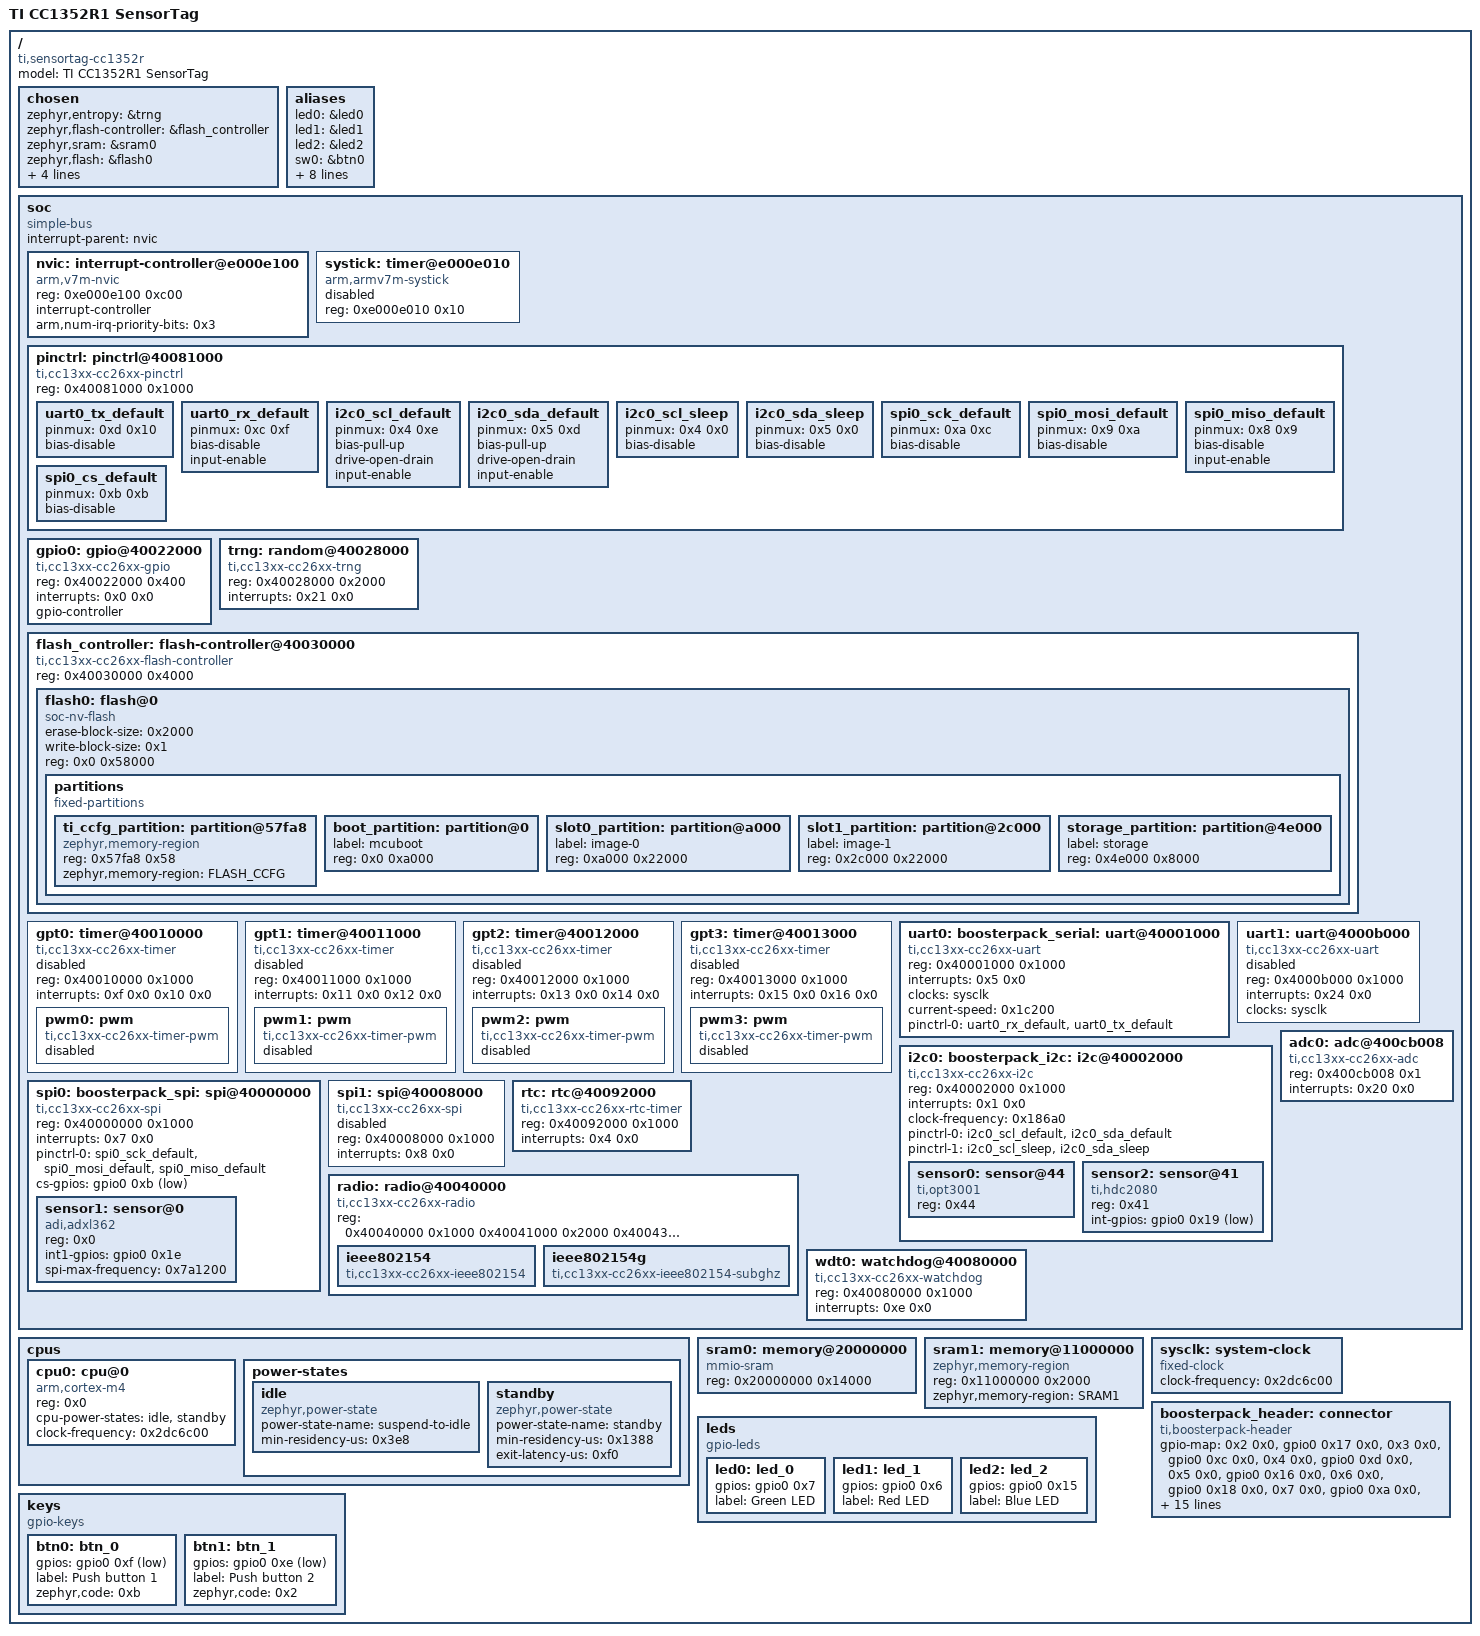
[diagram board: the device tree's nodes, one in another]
/dts-v1/;

/* node '/' defined in zephyr/dts/common/skeleton.dtsi:9 */
/ {
	#address-cells = < 0x1 >;            /* in zephyr/dts/common/skeleton.dtsi:10 */
	#size-cells = < 0x1 >;               /* in zephyr/dts/common/skeleton.dtsi:11 */
	model = "TI CC1352R1 SensorTag";     /* in zephyr/boards/ti/cc1352r_sensortag/cc1352r_sensortag.dts:18 */
	compatible = "ti,sensortag-cc1352r"; /* in zephyr/boards/ti/cc1352r_sensortag/cc1352r_sensortag.dts:19 */

	/* node '/chosen' defined in zephyr/dts/common/skeleton.dtsi:13 */
	chosen {
		zephyr,entropy = &trng;                      /* in zephyr/dts/arm/ti/cc13xx_cc26xx.dtsi:15 */
		zephyr,flash-controller = &flash_controller; /* in zephyr/dts/arm/ti/cc13xx_cc26xx.dtsi:16 */
		zephyr,sram = &sram0;                        /* in zephyr/boards/ti/cc1352r_sensortag/cc1352r_sensortag.dts:37 */
		zephyr,flash = &flash0;                      /* in zephyr/boards/ti/cc1352r_sensortag/cc1352r_sensortag.dts:38 */
		zephyr,console = &uart0;                     /* in zephyr/boards/ti/cc1352r_sensortag/cc1352r_sensortag.dts:39 */
		zephyr,shell-uart = &uart0;                  /* in zephyr/boards/ti/cc1352r_sensortag/cc1352r_sensortag.dts:40 */
		zephyr,ieee802154 = &ieee802154;             /* in zephyr/boards/ti/cc1352r_sensortag/cc1352r_sensortag.dts:41 */
		zephyr,code-partition = &slot0_partition;    /* in zephyr/boards/ti/cc1352r_sensortag/cc1352r_sensortag.dts:42 */
	};

	/* node '/aliases' defined in zephyr/dts/common/skeleton.dtsi:15 */
	aliases {
		led0 = &led0;            /* in zephyr/boards/ti/cc1352r_sensortag/cc1352r_sensortag.dts:22 */
		led1 = &led1;            /* in zephyr/boards/ti/cc1352r_sensortag/cc1352r_sensortag.dts:23 */
		led2 = &led2;            /* in zephyr/boards/ti/cc1352r_sensortag/cc1352r_sensortag.dts:24 */
		sw0 = &btn0;             /* in zephyr/boards/ti/cc1352r_sensortag/cc1352r_sensortag.dts:25 */
		sw1 = &btn1;             /* in zephyr/boards/ti/cc1352r_sensortag/cc1352r_sensortag.dts:26 */
		sensor0 = &sensor0;      /* in zephyr/boards/ti/cc1352r_sensortag/cc1352r_sensortag.dts:27 */
		sensor1 = &sensor1;      /* in zephyr/boards/ti/cc1352r_sensortag/cc1352r_sensortag.dts:28 */
		sensor2 = &sensor2;      /* in zephyr/boards/ti/cc1352r_sensortag/cc1352r_sensortag.dts:29 */
		accel0 = &sensor1;       /* in zephyr/boards/ti/cc1352r_sensortag/cc1352r_sensortag.dts:30 */
		watchdog0 = &wdt0;       /* in zephyr/boards/ti/cc1352r_sensortag/cc1352r_sensortag.dts:31 */
		mcuboot-led0 = &led1;    /* in zephyr/boards/ti/cc1352r_sensortag/cc1352r_sensortag.dts:32 */
		mcuboot-button0 = &btn1; /* in zephyr/boards/ti/cc1352r_sensortag/cc1352r_sensortag.dts:33 */
	};

	/* node '/soc' defined in zephyr/dts/arm/armv7-m.dtsi:6 */
	soc {
		#address-cells = < 0x1 >;     /* in zephyr/dts/arm/armv7-m.dtsi:7 */
		#size-cells = < 0x1 >;        /* in zephyr/dts/arm/armv7-m.dtsi:8 */
		compatible = "simple-bus";    /* in zephyr/dts/arm/armv7-m.dtsi:9 */
		interrupt-parent = < &nvic >; /* in zephyr/dts/arm/armv7-m.dtsi:10 */
		ranges;                       /* in zephyr/dts/arm/armv7-m.dtsi:11 */

		/* node '/soc/interrupt-controller@e000e100' defined in zephyr/dts/arm/armv7-m.dtsi:13 */
		nvic: interrupt-controller@e000e100 {
			#address-cells = < 0x1 >;            /* in zephyr/dts/arm/armv7-m.dtsi:14 */
			compatible = "arm,v7m-nvic";         /* in zephyr/dts/arm/armv7-m.dtsi:15 */
			reg = < 0xe000e100 0xc00 >;          /* in zephyr/dts/arm/armv7-m.dtsi:16 */
			interrupt-controller;                /* in zephyr/dts/arm/armv7-m.dtsi:17 */
			#interrupt-cells = < 0x2 >;          /* in zephyr/dts/arm/armv7-m.dtsi:18 */
			arm,num-irq-priority-bits = < 0x3 >; /* in zephyr/dts/arm/ti/cc13xx_cc26xx.dtsi:246 */
			phandle = < 0x1 >;                   /* in zephyr/dts/arm/armv7-m.dtsi:10 */
		};

		/* node '/soc/timer@e000e010' defined in zephyr/dts/arm/armv7-m.dtsi:21 */
		systick: timer@e000e010 {
			compatible = "arm,armv7m-systick"; /* in zephyr/dts/arm/armv7-m.dtsi:22 */
			reg = < 0xe000e010 0x10 >;         /* in zephyr/dts/arm/armv7-m.dtsi:23 */
			status = "disabled";               /* in zephyr/dts/arm/ti/cc13xx_cc26xx.dtsi:250 */
		};

		/* node '/soc/pinctrl@40081000' defined in zephyr/dts/arm/ti/cc13xx_cc26xx.dtsi:64 */
		pinctrl: pinctrl@40081000 {
			compatible = "ti,cc13xx-cc26xx-pinctrl"; /* in zephyr/dts/arm/ti/cc13xx_cc26xx.dtsi:65 */
			reg = < 0x40081000 0x1000 >;             /* in zephyr/dts/arm/ti/cc13xx_cc26xx.dtsi:66 */

			/* node '/soc/pinctrl@40081000/uart0_tx_default' defined in zephyr/boards/ti/cc1352r_sensortag/cc1352r_sensortag-pinctrl.dtsi:11 */
			uart0_tx_default: uart0_tx_default {
				pinmux = < 0xd 0x10 >; /* in zephyr/boards/ti/cc1352r_sensortag/cc1352r_sensortag-pinctrl.dtsi:12 */
				bias-disable;          /* in zephyr/boards/ti/cc1352r_sensortag/cc1352r_sensortag-pinctrl.dtsi:13 */
				phandle = < 0x4 >;     /* in zephyr/boards/ti/cc1352r_sensortag/cc1352r_sensortag.dts:131 */
			};

			/* node '/soc/pinctrl@40081000/uart0_rx_default' defined in zephyr/boards/ti/cc1352r_sensortag/cc1352r_sensortag-pinctrl.dtsi:16 */
			uart0_rx_default: uart0_rx_default {
				pinmux = < 0xc 0xf >; /* in zephyr/boards/ti/cc1352r_sensortag/cc1352r_sensortag-pinctrl.dtsi:17 */
				bias-disable;         /* in zephyr/boards/ti/cc1352r_sensortag/cc1352r_sensortag-pinctrl.dtsi:18 */
				input-enable;         /* in zephyr/boards/ti/cc1352r_sensortag/cc1352r_sensortag-pinctrl.dtsi:19 */
				phandle = < 0x3 >;    /* in zephyr/boards/ti/cc1352r_sensortag/cc1352r_sensortag.dts:131 */
			};

			/* node '/soc/pinctrl@40081000/i2c0_scl_default' defined in zephyr/boards/ti/cc1352r_sensortag/cc1352r_sensortag-pinctrl.dtsi:23 */
			i2c0_scl_default: i2c0_scl_default {
				pinmux = < 0x4 0xe >; /* in zephyr/boards/ti/cc1352r_sensortag/cc1352r_sensortag-pinctrl.dtsi:24 */
				bias-pull-up;         /* in zephyr/boards/ti/cc1352r_sensortag/cc1352r_sensortag-pinctrl.dtsi:25 */
				drive-open-drain;     /* in zephyr/boards/ti/cc1352r_sensortag/cc1352r_sensortag-pinctrl.dtsi:26 */
				input-enable;         /* in zephyr/boards/ti/cc1352r_sensortag/cc1352r_sensortag-pinctrl.dtsi:27 */
				phandle = < 0x5 >;    /* in zephyr/boards/ti/cc1352r_sensortag/cc1352r_sensortag.dts:137 */
			};

			/* node '/soc/pinctrl@40081000/i2c0_sda_default' defined in zephyr/boards/ti/cc1352r_sensortag/cc1352r_sensortag-pinctrl.dtsi:30 */
			i2c0_sda_default: i2c0_sda_default {
				pinmux = < 0x5 0xd >; /* in zephyr/boards/ti/cc1352r_sensortag/cc1352r_sensortag-pinctrl.dtsi:31 */
				bias-pull-up;         /* in zephyr/boards/ti/cc1352r_sensortag/cc1352r_sensortag-pinctrl.dtsi:32 */
				drive-open-drain;     /* in zephyr/boards/ti/cc1352r_sensortag/cc1352r_sensortag-pinctrl.dtsi:33 */
				input-enable;         /* in zephyr/boards/ti/cc1352r_sensortag/cc1352r_sensortag-pinctrl.dtsi:34 */
				phandle = < 0x6 >;    /* in zephyr/boards/ti/cc1352r_sensortag/cc1352r_sensortag.dts:137 */
			};

			/* node '/soc/pinctrl@40081000/i2c0_scl_sleep' defined in zephyr/boards/ti/cc1352r_sensortag/cc1352r_sensortag-pinctrl.dtsi:37 */
			i2c0_scl_sleep: i2c0_scl_sleep {
				pinmux = < 0x4 0x0 >; /* in zephyr/boards/ti/cc1352r_sensortag/cc1352r_sensortag-pinctrl.dtsi:38 */
				bias-disable;         /* in zephyr/boards/ti/cc1352r_sensortag/cc1352r_sensortag-pinctrl.dtsi:39 */
				phandle = < 0x7 >;    /* in zephyr/boards/ti/cc1352r_sensortag/cc1352r_sensortag.dts:138 */
			};

			/* node '/soc/pinctrl@40081000/i2c0_sda_sleep' defined in zephyr/boards/ti/cc1352r_sensortag/cc1352r_sensortag-pinctrl.dtsi:42 */
			i2c0_sda_sleep: i2c0_sda_sleep {
				pinmux = < 0x5 0x0 >; /* in zephyr/boards/ti/cc1352r_sensortag/cc1352r_sensortag-pinctrl.dtsi:43 */
				bias-disable;         /* in zephyr/boards/ti/cc1352r_sensortag/cc1352r_sensortag-pinctrl.dtsi:44 */
				phandle = < 0x8 >;    /* in zephyr/boards/ti/cc1352r_sensortag/cc1352r_sensortag.dts:138 */
			};

			/* node '/soc/pinctrl@40081000/spi0_sck_default' defined in zephyr/boards/ti/cc1352r_sensortag/cc1352r_sensortag-pinctrl.dtsi:48 */
			spi0_sck_default: spi0_sck_default {
				pinmux = < 0xa 0xc >; /* in zephyr/boards/ti/cc1352r_sensortag/cc1352r_sensortag-pinctrl.dtsi:49 */
				bias-disable;         /* in zephyr/boards/ti/cc1352r_sensortag/cc1352r_sensortag-pinctrl.dtsi:50 */
				phandle = < 0xa >;    /* in zephyr/boards/ti/cc1352r_sensortag/cc1352r_sensortag.dts:155 */
			};

			/* node '/soc/pinctrl@40081000/spi0_mosi_default' defined in zephyr/boards/ti/cc1352r_sensortag/cc1352r_sensortag-pinctrl.dtsi:53 */
			spi0_mosi_default: spi0_mosi_default {
				pinmux = < 0x9 0xa >; /* in zephyr/boards/ti/cc1352r_sensortag/cc1352r_sensortag-pinctrl.dtsi:54 */
				bias-disable;         /* in zephyr/boards/ti/cc1352r_sensortag/cc1352r_sensortag-pinctrl.dtsi:55 */
				phandle = < 0xb >;    /* in zephyr/boards/ti/cc1352r_sensortag/cc1352r_sensortag.dts:155 */
			};

			/* node '/soc/pinctrl@40081000/spi0_miso_default' defined in zephyr/boards/ti/cc1352r_sensortag/cc1352r_sensortag-pinctrl.dtsi:58 */
			spi0_miso_default: spi0_miso_default {
				pinmux = < 0x8 0x9 >; /* in zephyr/boards/ti/cc1352r_sensortag/cc1352r_sensortag-pinctrl.dtsi:59 */
				bias-disable;         /* in zephyr/boards/ti/cc1352r_sensortag/cc1352r_sensortag-pinctrl.dtsi:60 */
				input-enable;         /* in zephyr/boards/ti/cc1352r_sensortag/cc1352r_sensortag-pinctrl.dtsi:61 */
				phandle = < 0xc >;    /* in zephyr/boards/ti/cc1352r_sensortag/cc1352r_sensortag.dts:155 */
			};

			/* node '/soc/pinctrl@40081000/spi0_cs_default' defined in zephyr/boards/ti/cc1352r_sensortag/cc1352r_sensortag-pinctrl.dtsi:64 */
			spi0_cs_default: spi0_cs_default {
				pinmux = < 0xb 0xb >; /* in zephyr/boards/ti/cc1352r_sensortag/cc1352r_sensortag-pinctrl.dtsi:65 */
				bias-disable;         /* in zephyr/boards/ti/cc1352r_sensortag/cc1352r_sensortag-pinctrl.dtsi:66 */
			};
		};

		/* node '/soc/gpio@40022000' defined in zephyr/dts/arm/ti/cc13xx_cc26xx.dtsi:69 */
		gpio0: gpio@40022000 {
			compatible = "ti,cc13xx-cc26xx-gpio"; /* in zephyr/dts/arm/ti/cc13xx_cc26xx.dtsi:70 */
			reg = < 0x40022000 0x400 >;           /* in zephyr/dts/arm/ti/cc13xx_cc26xx.dtsi:71 */
			interrupts = < 0x0 0x0 >;             /* in zephyr/dts/arm/ti/cc13xx_cc26xx.dtsi:72 */
			gpio-controller;                      /* in zephyr/dts/arm/ti/cc13xx_cc26xx.dtsi:74 */
			#gpio-cells = < 0x2 >;                /* in zephyr/dts/arm/ti/cc13xx_cc26xx.dtsi:75 */
			status = "okay";                      /* in zephyr/boards/ti/cc1352r_sensortag/cc1352r_sensortag.dts:121 */
			phandle = < 0x9 >;                    /* in zephyr/boards/ti/cc1352r_sensortag/cc1352r_sensortag.dts:149 */
		};

		/* node '/soc/random@40028000' defined in zephyr/dts/arm/ti/cc13xx_cc26xx.dtsi:78 */
		trng: random@40028000 {
			compatible = "ti,cc13xx-cc26xx-trng"; /* in zephyr/dts/arm/ti/cc13xx_cc26xx.dtsi:79 */
			reg = < 0x40028000 0x2000 >;          /* in zephyr/dts/arm/ti/cc13xx_cc26xx.dtsi:80 */
			interrupts = < 0x21 0x0 >;            /* in zephyr/dts/arm/ti/cc13xx_cc26xx.dtsi:81 */
			status = "okay";                      /* in zephyr/boards/ti/cc1352r_sensortag/cc1352r_sensortag.dts:117 */
		};

		/* node '/soc/flash-controller@40030000' defined in zephyr/dts/arm/ti/cc13xx_cc26xx.dtsi:85 */
		flash_controller: flash-controller@40030000 {
			compatible = "ti,cc13xx-cc26xx-flash-controller"; /* in zephyr/dts/arm/ti/cc13xx_cc26xx.dtsi:86 */
			reg = < 0x40030000 0x4000 >;                      /* in zephyr/dts/arm/ti/cc13xx_cc26xx.dtsi:87 */
			#address-cells = < 0x1 >;                         /* in zephyr/dts/arm/ti/cc13xx_cc26xx.dtsi:89 */
			#size-cells = < 0x1 >;                            /* in zephyr/dts/arm/ti/cc13xx_cc26xx.dtsi:90 */

			/* node '/soc/flash-controller@40030000/flash@0' defined in zephyr/dts/arm/ti/cc13xx_cc26xx.dtsi:92 */
			flash0: flash@0 {
				compatible = "soc-nv-flash";   /* in zephyr/dts/arm/ti/cc13xx_cc26xx.dtsi:93 */
				erase-block-size = < 0x2000 >; /* in zephyr/dts/arm/ti/cc13xx_cc26xx.dtsi:94 */
				write-block-size = < 0x1 >;    /* in zephyr/dts/arm/ti/cc13xx_cc26xx.dtsi:95 */
				reg = < 0x0 0x58000 >;         /* in zephyr/dts/arm/ti/cc1352r.dtsi:17 */

				/* node '/soc/flash-controller@40030000/flash@0/partitions' defined in zephyr/dts/arm/ti/cc1352r.dtsi:19 */
				partitions {
					compatible = "fixed-partitions"; /* in zephyr/dts/arm/ti/cc1352r.dtsi:20 */
					#address-cells = < 0x1 >;        /* in zephyr/dts/arm/ti/cc1352r.dtsi:21 */
					#size-cells = < 0x1 >;           /* in zephyr/dts/arm/ti/cc1352r.dtsi:22 */

					/* node '/soc/flash-controller@40030000/flash@0/partitions/partition@57fa8' defined in zephyr/dts/arm/ti/cc1352r.dtsi:25 */
					ti_ccfg_partition: partition@57fa8 {
						compatible = "zephyr,memory-region"; /* in zephyr/dts/arm/ti/cc1352r.dtsi:26 */
						reg = < 0x57fa8 0x58 >;              /* in zephyr/dts/arm/ti/cc1352r.dtsi:27 */
						zephyr,memory-region = "FLASH_CCFG"; /* in zephyr/dts/arm/ti/cc1352r.dtsi:28 */
					};

					/* node '/soc/flash-controller@40030000/flash@0/partitions/partition@0' defined in zephyr/boards/ti/cc1352r_sensortag/cc1352r_sensortag.dts:84 */
					boot_partition: partition@0 {
						label = "mcuboot";    /* in zephyr/boards/ti/cc1352r_sensortag/cc1352r_sensortag.dts:85 */
						reg = < 0x0 0xa000 >; /* in zephyr/boards/ti/cc1352r_sensortag/cc1352r_sensortag.dts:86 */
					};

					/* node '/soc/flash-controller@40030000/flash@0/partitions/partition@a000' defined in zephyr/boards/ti/cc1352r_sensortag/cc1352r_sensortag.dts:90 */
					slot0_partition: partition@a000 {
						label = "image-0";        /* in zephyr/boards/ti/cc1352r_sensortag/cc1352r_sensortag.dts:91 */
						reg = < 0xa000 0x22000 >; /* in zephyr/boards/ti/cc1352r_sensortag/cc1352r_sensortag.dts:92 */
					};

					/* node '/soc/flash-controller@40030000/flash@0/partitions/partition@2c000' defined in zephyr/boards/ti/cc1352r_sensortag/cc1352r_sensortag.dts:95 */
					slot1_partition: partition@2c000 {
						label = "image-1";         /* in zephyr/boards/ti/cc1352r_sensortag/cc1352r_sensortag.dts:96 */
						reg = < 0x2c000 0x22000 >; /* in zephyr/boards/ti/cc1352r_sensortag/cc1352r_sensortag.dts:97 */
					};

					/* node '/soc/flash-controller@40030000/flash@0/partitions/partition@4e000' defined in zephyr/boards/ti/cc1352r_sensortag/cc1352r_sensortag.dts:101 */
					storage_partition: partition@4e000 {
						label = "storage";        /* in zephyr/boards/ti/cc1352r_sensortag/cc1352r_sensortag.dts:102 */
						reg = < 0x4e000 0x8000 >; /* in zephyr/boards/ti/cc1352r_sensortag/cc1352r_sensortag.dts:103 */
					};
				};
			};
		};

		/* node '/soc/timer@40010000' defined in zephyr/dts/arm/ti/cc13xx_cc26xx.dtsi:99 */
		gpt0: timer@40010000 {
			compatible = "ti,cc13xx-cc26xx-timer"; /* in zephyr/dts/arm/ti/cc13xx_cc26xx.dtsi:100 */
			reg = < 0x40010000 0x1000 >;           /* in zephyr/dts/arm/ti/cc13xx_cc26xx.dtsi:101 */
			interrupts = < 0xf 0x0 0x10 0x0 >;     /* in zephyr/dts/arm/ti/cc13xx_cc26xx.dtsi:102 */
			interrupt-names = "gpt0a",
			                  "gpt0b";             /* in zephyr/dts/arm/ti/cc13xx_cc26xx.dtsi:103 */
			status = "disabled";                   /* in zephyr/dts/arm/ti/cc13xx_cc26xx.dtsi:104 */

			/* node '/soc/timer@40010000/pwm' defined in zephyr/dts/arm/ti/cc13xx_cc26xx.dtsi:106 */
			pwm0: pwm {
				compatible = "ti,cc13xx-cc26xx-timer-pwm"; /* in zephyr/dts/arm/ti/cc13xx_cc26xx.dtsi:107 */
				#pwm-cells = < 0x3 >;                      /* in zephyr/dts/arm/ti/cc13xx_cc26xx.dtsi:108 */
				status = "disabled";                       /* in zephyr/dts/arm/ti/cc13xx_cc26xx.dtsi:109 */
			};
		};

		/* node '/soc/timer@40011000' defined in zephyr/dts/arm/ti/cc13xx_cc26xx.dtsi:113 */
		gpt1: timer@40011000 {
			compatible = "ti,cc13xx-cc26xx-timer"; /* in zephyr/dts/arm/ti/cc13xx_cc26xx.dtsi:114 */
			reg = < 0x40011000 0x1000 >;           /* in zephyr/dts/arm/ti/cc13xx_cc26xx.dtsi:115 */
			interrupts = < 0x11 0x0 0x12 0x0 >;    /* in zephyr/dts/arm/ti/cc13xx_cc26xx.dtsi:116 */
			interrupt-names = "gpt1a",
			                  "gpt1b";             /* in zephyr/dts/arm/ti/cc13xx_cc26xx.dtsi:117 */
			status = "disabled";                   /* in zephyr/dts/arm/ti/cc13xx_cc26xx.dtsi:118 */

			/* node '/soc/timer@40011000/pwm' defined in zephyr/dts/arm/ti/cc13xx_cc26xx.dtsi:120 */
			pwm1: pwm {
				compatible = "ti,cc13xx-cc26xx-timer-pwm"; /* in zephyr/dts/arm/ti/cc13xx_cc26xx.dtsi:121 */
				#pwm-cells = < 0x3 >;                      /* in zephyr/dts/arm/ti/cc13xx_cc26xx.dtsi:122 */
				status = "disabled";                       /* in zephyr/dts/arm/ti/cc13xx_cc26xx.dtsi:123 */
			};
		};

		/* node '/soc/timer@40012000' defined in zephyr/dts/arm/ti/cc13xx_cc26xx.dtsi:127 */
		gpt2: timer@40012000 {
			compatible = "ti,cc13xx-cc26xx-timer"; /* in zephyr/dts/arm/ti/cc13xx_cc26xx.dtsi:128 */
			reg = < 0x40012000 0x1000 >;           /* in zephyr/dts/arm/ti/cc13xx_cc26xx.dtsi:129 */
			interrupts = < 0x13 0x0 0x14 0x0 >;    /* in zephyr/dts/arm/ti/cc13xx_cc26xx.dtsi:130 */
			interrupt-names = "gpt2a",
			                  "gpt2b";             /* in zephyr/dts/arm/ti/cc13xx_cc26xx.dtsi:131 */
			status = "disabled";                   /* in zephyr/dts/arm/ti/cc13xx_cc26xx.dtsi:132 */

			/* node '/soc/timer@40012000/pwm' defined in zephyr/dts/arm/ti/cc13xx_cc26xx.dtsi:134 */
			pwm2: pwm {
				compatible = "ti,cc13xx-cc26xx-timer-pwm"; /* in zephyr/dts/arm/ti/cc13xx_cc26xx.dtsi:135 */
				#pwm-cells = < 0x3 >;                      /* in zephyr/dts/arm/ti/cc13xx_cc26xx.dtsi:136 */
				status = "disabled";                       /* in zephyr/dts/arm/ti/cc13xx_cc26xx.dtsi:137 */
			};
		};

		/* node '/soc/timer@40013000' defined in zephyr/dts/arm/ti/cc13xx_cc26xx.dtsi:141 */
		gpt3: timer@40013000 {
			compatible = "ti,cc13xx-cc26xx-timer"; /* in zephyr/dts/arm/ti/cc13xx_cc26xx.dtsi:142 */
			reg = < 0x40013000 0x1000 >;           /* in zephyr/dts/arm/ti/cc13xx_cc26xx.dtsi:143 */
			interrupts = < 0x15 0x0 0x16 0x0 >;    /* in zephyr/dts/arm/ti/cc13xx_cc26xx.dtsi:144 */
			interrupt-names = "gpt3a",
			                  "gpt3b";             /* in zephyr/dts/arm/ti/cc13xx_cc26xx.dtsi:145 */
			status = "disabled";                   /* in zephyr/dts/arm/ti/cc13xx_cc26xx.dtsi:146 */

			/* node '/soc/timer@40013000/pwm' defined in zephyr/dts/arm/ti/cc13xx_cc26xx.dtsi:148 */
			pwm3: pwm {
				compatible = "ti,cc13xx-cc26xx-timer-pwm"; /* in zephyr/dts/arm/ti/cc13xx_cc26xx.dtsi:149 */
				#pwm-cells = < 0x3 >;                      /* in zephyr/dts/arm/ti/cc13xx_cc26xx.dtsi:150 */
				status = "disabled";                       /* in zephyr/dts/arm/ti/cc13xx_cc26xx.dtsi:151 */
			};
		};

		/* node '/soc/uart@40001000' defined in zephyr/dts/arm/ti/cc13xx_cc26xx.dtsi:155 */
		uart0: boosterpack_serial: uart@40001000 {
			compatible = "ti,cc13xx-cc26xx-uart";                /* in zephyr/dts/arm/ti/cc13xx_cc26xx.dtsi:156 */
			reg = < 0x40001000 0x1000 >;                         /* in zephyr/dts/arm/ti/cc13xx_cc26xx.dtsi:157 */
			interrupts = < 0x5 0x0 >;                            /* in zephyr/dts/arm/ti/cc13xx_cc26xx.dtsi:158 */
			clocks = < &sysclk >;                                /* in zephyr/dts/arm/ti/cc13xx_cc26xx.dtsi:159 */
			status = "okay";                                     /* in zephyr/boards/ti/cc1352r_sensortag/cc1352r_sensortag.dts:129 */
			current-speed = < 0x1c200 >;                         /* in zephyr/boards/ti/cc1352r_sensortag/cc1352r_sensortag.dts:130 */
			pinctrl-0 = < &uart0_rx_default &uart0_tx_default >; /* in zephyr/boards/ti/cc1352r_sensortag/cc1352r_sensortag.dts:131 */
			pinctrl-names = "default";                           /* in zephyr/boards/ti/cc1352r_sensortag/cc1352r_sensortag.dts:132 */
		};

		/* node '/soc/uart@4000b000' defined in zephyr/dts/arm/ti/cc13xx_cc26xx.dtsi:163 */
		uart1: uart@4000b000 {
			compatible = "ti,cc13xx-cc26xx-uart"; /* in zephyr/dts/arm/ti/cc13xx_cc26xx.dtsi:164 */
			reg = < 0x4000b000 0x1000 >;          /* in zephyr/dts/arm/ti/cc13xx_cc26xx.dtsi:165 */
			interrupts = < 0x24 0x0 >;            /* in zephyr/dts/arm/ti/cc13xx_cc26xx.dtsi:166 */
			clocks = < &sysclk >;                 /* in zephyr/dts/arm/ti/cc13xx_cc26xx.dtsi:167 */
			status = "disabled";                  /* in zephyr/dts/arm/ti/cc13xx_cc26xx.dtsi:168 */
		};

		/* node '/soc/i2c@40002000' defined in zephyr/dts/arm/ti/cc13xx_cc26xx.dtsi:171 */
		i2c0: boosterpack_i2c: i2c@40002000 {
			compatible = "ti,cc13xx-cc26xx-i2c";                 /* in zephyr/dts/arm/ti/cc13xx_cc26xx.dtsi:172 */
			#address-cells = < 0x1 >;                            /* in zephyr/dts/arm/ti/cc13xx_cc26xx.dtsi:173 */
			#size-cells = < 0x0 >;                               /* in zephyr/dts/arm/ti/cc13xx_cc26xx.dtsi:174 */
			reg = < 0x40002000 0x1000 >;                         /* in zephyr/dts/arm/ti/cc13xx_cc26xx.dtsi:175 */
			interrupts = < 0x1 0x0 >;                            /* in zephyr/dts/arm/ti/cc13xx_cc26xx.dtsi:176 */
			clock-frequency = < 0x186a0 >;                       /* in zephyr/dts/arm/ti/cc13xx_cc26xx.dtsi:177 */
			status = "okay";                                     /* in zephyr/boards/ti/cc1352r_sensortag/cc1352r_sensortag.dts:136 */
			pinctrl-0 = < &i2c0_scl_default &i2c0_sda_default >; /* in zephyr/boards/ti/cc1352r_sensortag/cc1352r_sensortag.dts:137 */
			pinctrl-1 = < &i2c0_scl_sleep &i2c0_sda_sleep >;     /* in zephyr/boards/ti/cc1352r_sensortag/cc1352r_sensortag.dts:138 */
			pinctrl-names = "default",
			                "sleep";                             /* in zephyr/boards/ti/cc1352r_sensortag/cc1352r_sensortag.dts:139 */

			/* node '/soc/i2c@40002000/sensor@44' defined in zephyr/boards/ti/cc1352r_sensortag/cc1352r_sensortag.dts:141 */
			sensor0: sensor@44 {
				compatible = "ti,opt3001"; /* in zephyr/boards/ti/cc1352r_sensortag/cc1352r_sensortag.dts:142 */
				reg = < 0x44 >;            /* in zephyr/boards/ti/cc1352r_sensortag/cc1352r_sensortag.dts:143 */
			};

			/* node '/soc/i2c@40002000/sensor@41' defined in zephyr/boards/ti/cc1352r_sensortag/cc1352r_sensortag.dts:146 */
			sensor2: sensor@41 {
				compatible = "ti,hdc2080";       /* in zephyr/boards/ti/cc1352r_sensortag/cc1352r_sensortag.dts:147 */
				reg = < 0x41 >;                  /* in zephyr/boards/ti/cc1352r_sensortag/cc1352r_sensortag.dts:148 */
				int-gpios = < &gpio0 0x19 0x1 >; /* in zephyr/boards/ti/cc1352r_sensortag/cc1352r_sensortag.dts:149 */
			};
		};

		/* node '/soc/spi@40000000' defined in zephyr/dts/arm/ti/cc13xx_cc26xx.dtsi:181 */
		spi0: boosterpack_spi: spi@40000000 {
			compatible = "ti,cc13xx-cc26xx-spi";                                     /* in zephyr/dts/arm/ti/cc13xx_cc26xx.dtsi:182 */
			#address-cells = < 0x1 >;                                                /* in zephyr/dts/arm/ti/cc13xx_cc26xx.dtsi:183 */
			#size-cells = < 0x0 >;                                                   /* in zephyr/dts/arm/ti/cc13xx_cc26xx.dtsi:184 */
			reg = < 0x40000000 0x1000 >;                                             /* in zephyr/dts/arm/ti/cc13xx_cc26xx.dtsi:185 */
			interrupts = < 0x7 0x0 >;                                                /* in zephyr/dts/arm/ti/cc13xx_cc26xx.dtsi:186 */
			status = "okay";                                                         /* in zephyr/boards/ti/cc1352r_sensortag/cc1352r_sensortag.dts:154 */
			pinctrl-0 = < &spi0_sck_default &spi0_mosi_default &spi0_miso_default >; /* in zephyr/boards/ti/cc1352r_sensortag/cc1352r_sensortag.dts:155 */
			pinctrl-names = "default";                                               /* in zephyr/boards/ti/cc1352r_sensortag/cc1352r_sensortag.dts:157 */
			cs-gpios = < &gpio0 0xb 0x1 >;                                           /* in zephyr/boards/ti/cc1352r_sensortag/cc1352r_sensortag.dts:158 */

			/* node '/soc/spi@40000000/sensor@0' defined in zephyr/boards/ti/cc1352r_sensortag/cc1352r_sensortag.dts:160 */
			sensor1: sensor@0 {
				compatible = "adi,adxl362";       /* in zephyr/boards/ti/cc1352r_sensortag/cc1352r_sensortag.dts:161 */
				reg = < 0x0 >;                    /* in zephyr/boards/ti/cc1352r_sensortag/cc1352r_sensortag.dts:162 */
				int1-gpios = < &gpio0 0x1e 0x0 >; /* in zephyr/boards/ti/cc1352r_sensortag/cc1352r_sensortag.dts:163 */
				spi-max-frequency = < 0x7a1200 >; /* in zephyr/boards/ti/cc1352r_sensortag/cc1352r_sensortag.dts:164 */
			};
		};

		/* node '/soc/spi@40008000' defined in zephyr/dts/arm/ti/cc13xx_cc26xx.dtsi:190 */
		spi1: spi@40008000 {
			compatible = "ti,cc13xx-cc26xx-spi"; /* in zephyr/dts/arm/ti/cc13xx_cc26xx.dtsi:191 */
			#address-cells = < 0x1 >;            /* in zephyr/dts/arm/ti/cc13xx_cc26xx.dtsi:192 */
			#size-cells = < 0x0 >;               /* in zephyr/dts/arm/ti/cc13xx_cc26xx.dtsi:193 */
			reg = < 0x40008000 0x1000 >;         /* in zephyr/dts/arm/ti/cc13xx_cc26xx.dtsi:194 */
			interrupts = < 0x8 0x0 >;            /* in zephyr/dts/arm/ti/cc13xx_cc26xx.dtsi:195 */
			status = "disabled";                 /* in zephyr/dts/arm/ti/cc13xx_cc26xx.dtsi:196 */
		};

		/* node '/soc/rtc@40092000' defined in zephyr/dts/arm/ti/cc13xx_cc26xx.dtsi:200 */
		rtc: rtc@40092000 {
			compatible = "ti,cc13xx-cc26xx-rtc-timer"; /* in zephyr/dts/arm/ti/cc13xx_cc26xx.dtsi:201 */
			reg = < 0x40092000 0x1000 >;               /* in zephyr/dts/arm/ti/cc13xx_cc26xx.dtsi:202 */
			interrupts = < 0x4 0x0 >;                  /* in zephyr/dts/arm/ti/cc13xx_cc26xx.dtsi:203 */
			status = "okay";                           /* in zephyr/dts/arm/ti/cc13xx_cc26xx.dtsi:204 */
		};

		/* node '/soc/radio@40040000' defined in zephyr/dts/arm/ti/cc13xx_cc26xx.dtsi:207 */
		radio: radio@40040000 {
			compatible = "ti,cc13xx-cc26xx-radio";                                             /* in zephyr/dts/arm/ti/cc13xx_cc26xx.dtsi:208 */
			reg = < 0x40040000 0x1000 0x40041000 0x2000 0x40043000 0x1000 0x40044000 0x1000 >; /* in zephyr/dts/arm/ti/cc13xx_cc26xx.dtsi:211 */
			reg-names = "RFC_PWR",
			            "RFC_DBELL",
			            "RFC_RAT",
			            "RFC_FSCA";                                                            /* in zephyr/dts/arm/ti/cc13xx_cc26xx.dtsi:215 */
			status = "okay";                                                                   /* in zephyr/boards/ti/cc1352r_sensortag/cc1352r_sensortag.dts:171 */

			/* node '/soc/radio@40040000/ieee802154' defined in zephyr/dts/arm/ti/cc13xx_cc26xx.dtsi:217 */
			ieee802154: ieee802154 {
				compatible = "ti,cc13xx-cc26xx-ieee802154"; /* in zephyr/dts/arm/ti/cc13xx_cc26xx.dtsi:218 */
				status = "okay";                            /* in zephyr/boards/ti/cc1352r_sensortag/cc1352r_sensortag.dts:175 */
			};

			/* node '/soc/radio@40040000/ieee802154g' defined in zephyr/dts/arm/ti/cc13xx_cc26xx.dtsi:222 */
			ieee802154g: ieee802154g {
				compatible = "ti,cc13xx-cc26xx-ieee802154-subghz"; /* in zephyr/dts/arm/ti/cc13xx_cc26xx.dtsi:223 */
				status = "okay";                                   /* in zephyr/boards/ti/cc1352r_sensortag/cc1352r_sensortag.dts:179 */
			};
		};

		/* node '/soc/watchdog@40080000' defined in zephyr/dts/arm/ti/cc13xx_cc26xx.dtsi:228 */
		wdt0: watchdog@40080000 {
			compatible = "ti,cc13xx-cc26xx-watchdog"; /* in zephyr/dts/arm/ti/cc13xx_cc26xx.dtsi:229 */
			reg = < 0x40080000 0x1000 >;              /* in zephyr/dts/arm/ti/cc13xx_cc26xx.dtsi:230 */
			interrupts = < 0xe 0x0 >;                 /* in zephyr/dts/arm/ti/cc13xx_cc26xx.dtsi:231 */
			status = "okay";                          /* in zephyr/boards/ti/cc1352r_sensortag/cc1352r_sensortag.dts:183 */
		};

		/* node '/soc/adc@400cb008' defined in zephyr/dts/arm/ti/cc13xx_cc26xx.dtsi:235 */
		adc0: adc@400cb008 {
			compatible = "ti,cc13xx-cc26xx-adc"; /* in zephyr/dts/arm/ti/cc13xx_cc26xx.dtsi:236 */
			reg = < 0x400cb008 0x1 >;            /* in zephyr/dts/arm/ti/cc13xx_cc26xx.dtsi:237 */
			interrupts = < 0x20 0x0 >;           /* in zephyr/dts/arm/ti/cc13xx_cc26xx.dtsi:238 */
			#io-channel-cells = < 0x1 >;         /* in zephyr/dts/arm/ti/cc13xx_cc26xx.dtsi:240 */
			status = "okay";                     /* in zephyr/boards/ti/cc1352r_sensortag/cc1352r_sensortag.dts:125 */
		};
	};

	/* node '/cpus' defined in zephyr/dts/arm/ti/cc13xx_cc26xx.dtsi:19 */
	cpus {
		#address-cells = < 0x1 >; /* in zephyr/dts/arm/ti/cc13xx_cc26xx.dtsi:20 */
		#size-cells = < 0x0 >;    /* in zephyr/dts/arm/ti/cc13xx_cc26xx.dtsi:21 */

		/* node '/cpus/cpu@0' defined in zephyr/dts/arm/ti/cc13xx_cc26xx.dtsi:23 */
		cpu0: cpu@0 {
			device_type = "cpu";                   /* in zephyr/dts/arm/ti/cc13xx_cc26xx.dtsi:24 */
			compatible = "arm,cortex-m4";          /* in zephyr/dts/arm/ti/cc13xx_cc26xx.dtsi:25 */
			reg = < 0x0 >;                         /* in zephyr/dts/arm/ti/cc13xx_cc26xx.dtsi:26 */
			cpu-power-states = < &idle &standby >; /* in zephyr/dts/arm/ti/cc13xx_cc26xx.dtsi:27 */
			clock-frequency = < 0x2dc6c00 >;       /* in zephyr/boards/ti/cc1352r_sensortag/cc1352r_sensortag.dts:113 */
		};

		/* node '/cpus/power-states' defined in zephyr/dts/arm/ti/cc13xx_cc26xx.dtsi:30 */
		power-states {

			/* node '/cpus/power-states/idle' defined in zephyr/dts/arm/ti/cc13xx_cc26xx.dtsi:31 */
			idle: idle {
				compatible = "zephyr,power-state";    /* in zephyr/dts/arm/ti/cc13xx_cc26xx.dtsi:32 */
				power-state-name = "suspend-to-idle"; /* in zephyr/dts/arm/ti/cc13xx_cc26xx.dtsi:33 */
				min-residency-us = < 0x3e8 >;         /* in zephyr/dts/arm/ti/cc13xx_cc26xx.dtsi:34 */
				phandle = < 0xd >;                    /* in zephyr/dts/arm/ti/cc13xx_cc26xx.dtsi:27 */
			};

			/* node '/cpus/power-states/standby' defined in zephyr/dts/arm/ti/cc13xx_cc26xx.dtsi:37 */
			standby: standby {
				compatible = "zephyr,power-state"; /* in zephyr/dts/arm/ti/cc13xx_cc26xx.dtsi:38 */
				power-state-name = "standby";      /* in zephyr/dts/arm/ti/cc13xx_cc26xx.dtsi:39 */
				min-residency-us = < 0x1388 >;     /* in zephyr/dts/arm/ti/cc13xx_cc26xx.dtsi:40 */
				exit-latency-us = < 0xf0 >;        /* in zephyr/dts/arm/ti/cc13xx_cc26xx.dtsi:41 */
				phandle = < 0xe >;                 /* in zephyr/dts/arm/ti/cc13xx_cc26xx.dtsi:27 */
			};
		};
	};

	/* node '/memory@20000000' defined in zephyr/dts/arm/ti/cc13xx_cc26xx.dtsi:46 */
	sram0: memory@20000000 {
		compatible = "mmio-sram";     /* in zephyr/dts/arm/ti/cc13xx_cc26xx.dtsi:47 */
		reg = < 0x20000000 0x14000 >; /* in zephyr/dts/arm/ti/cc1352r.dtsi:12 */
	};

	/* node '/memory@11000000' defined in zephyr/dts/arm/ti/cc13xx_cc26xx.dtsi:51 */
	sram1: memory@11000000 {
		compatible = "zephyr,memory-region",
		             "mmio-sram";            /* in zephyr/dts/arm/ti/cc13xx_cc26xx.dtsi:52 */
		reg = < 0x11000000 0x2000 >;         /* in zephyr/dts/arm/ti/cc13xx_cc26xx.dtsi:53 */
		zephyr,memory-region = "SRAM1";      /* in zephyr/dts/arm/ti/cc13xx_cc26xx.dtsi:54 */
	};

	/* node '/system-clock' defined in zephyr/dts/arm/ti/cc13xx_cc26xx.dtsi:57 */
	sysclk: system-clock {
		compatible = "fixed-clock";      /* in zephyr/dts/arm/ti/cc13xx_cc26xx.dtsi:58 */
		clock-frequency = < 0x2dc6c00 >; /* in zephyr/dts/arm/ti/cc13xx_cc26xx.dtsi:59 */
		#clock-cells = < 0x0 >;          /* in zephyr/dts/arm/ti/cc13xx_cc26xx.dtsi:60 */
		phandle = < 0x2 >;               /* in zephyr/dts/arm/ti/cc13xx_cc26xx.dtsi:159 */
	};

	/* node '/connector' defined in zephyr/boards/ti/common/boosterpack_connector.dtsi:8 */
	boosterpack_header: connector {
		compatible = "ti,boosterpack-header";    /* in zephyr/boards/ti/common/boosterpack_connector.dtsi:9 */
		#gpio-cells = < 0x2 >;                   /* in zephyr/boards/ti/common/boosterpack_connector.dtsi:10 */
		gpio-map = < 0x2 0x0 &gpio0 0x17 0x0 >,
		           < 0x3 0x0 &gpio0 0xc 0x0 >,
		           < 0x4 0x0 &gpio0 0xd 0x0 >,
		           < 0x5 0x0 &gpio0 0x16 0x0 >,
		           < 0x6 0x0 &gpio0 0x18 0x0 >,
		           < 0x7 0x0 &gpio0 0xa 0x0 >,
		           < 0x8 0x0 &gpio0 0x15 0x0 >,
		           < 0x9 0x0 &gpio0 0x4 0x0 >,
		           < 0xa 0x0 &gpio0 0x5 0x0 >,
		           < 0xc 0x0 &gpio0 0xe 0x0 >,
		           < 0xd 0x0 &gpio0 0xf 0x0 >,
		           < 0xe 0x0 &gpio0 0x8 0x0 >,
		           < 0xf 0x0 &gpio0 0x9 0x0 >,
		           < 0x12 0x0 &gpio0 0xb 0x0 >,
		           < 0x13 0x0 &gpio0 0x3 0x0 >,
		           < 0x17 0x0 &gpio0 0x19 0x0 >,
		           < 0x18 0x0 &gpio0 0x1a 0x0 >,
		           < 0x19 0x0 &gpio0 0x1b 0x0 >,
		           < 0x1a 0x0 &gpio0 0x1c 0x0 >,
		           < 0x1b 0x0 &gpio0 0x1d 0x0 >,
		           < 0x1c 0x0 &gpio0 0x1e 0x0 >,
		           < 0x1f 0x0 &gpio0 0x11 0x0 >,
		           < 0x20 0x0 &gpio0 0x10 0x0 >,
		           < 0x24 0x0 &gpio0 0x12 0x0 >,
		           < 0x25 0x0 &gpio0 0x13 0x0 >,
		           < 0x26 0x0 &gpio0 0x14 0x0 >,
		           < 0x27 0x0 &gpio0 0x6 0x0 >,
		           < 0x28 0x0 &gpio0 0x7 0x0 >;  /* in zephyr/boards/ti/common/boosterpack_connector.dtsi:11 */
	};

	/* node '/leds' defined in zephyr/boards/ti/cc1352r_sensortag/cc1352r_sensortag.dts:45 */
	leds {
		compatible = "gpio-leds"; /* in zephyr/boards/ti/cc1352r_sensortag/cc1352r_sensortag.dts:46 */

		/* node '/leds/led_0' defined in zephyr/boards/ti/cc1352r_sensortag/cc1352r_sensortag.dts:48 */
		led0: led_0 {
			gpios = < &gpio0 0x7 0x0 >; /* in zephyr/boards/ti/cc1352r_sensortag/cc1352r_sensortag.dts:49 */
			label = "Green LED";        /* in zephyr/boards/ti/cc1352r_sensortag/cc1352r_sensortag.dts:50 */
		};

		/* node '/leds/led_1' defined in zephyr/boards/ti/cc1352r_sensortag/cc1352r_sensortag.dts:53 */
		led1: led_1 {
			gpios = < &gpio0 0x6 0x0 >; /* in zephyr/boards/ti/cc1352r_sensortag/cc1352r_sensortag.dts:54 */
			label = "Red LED";          /* in zephyr/boards/ti/cc1352r_sensortag/cc1352r_sensortag.dts:55 */
		};

		/* node '/leds/led_2' defined in zephyr/boards/ti/cc1352r_sensortag/cc1352r_sensortag.dts:58 */
		led2: led_2 {
			gpios = < &gpio0 0x15 0x0 >; /* in zephyr/boards/ti/cc1352r_sensortag/cc1352r_sensortag.dts:59 */
			label = "Blue LED";          /* in zephyr/boards/ti/cc1352r_sensortag/cc1352r_sensortag.dts:60 */
		};
	};

	/* node '/keys' defined in zephyr/boards/ti/cc1352r_sensortag/cc1352r_sensortag.dts:64 */
	keys {
		compatible = "gpio-keys"; /* in zephyr/boards/ti/cc1352r_sensortag/cc1352r_sensortag.dts:65 */

		/* node '/keys/btn_0' defined in zephyr/boards/ti/cc1352r_sensortag/cc1352r_sensortag.dts:67 */
		btn0: btn_0 {
			gpios = < &gpio0 0xf 0x11 >; /* in zephyr/boards/ti/cc1352r_sensortag/cc1352r_sensortag.dts:68 */
			label = "Push button 1";     /* in zephyr/boards/ti/cc1352r_sensortag/cc1352r_sensortag.dts:69 */
			zephyr,code = < 0xb >;       /* in zephyr/boards/ti/cc1352r_sensortag/cc1352r_sensortag.dts:70 */
		};

		/* node '/keys/btn_1' defined in zephyr/boards/ti/cc1352r_sensortag/cc1352r_sensortag.dts:73 */
		btn1: btn_1 {
			gpios = < &gpio0 0xe 0x11 >; /* in zephyr/boards/ti/cc1352r_sensortag/cc1352r_sensortag.dts:74 */
			label = "Push button 2";     /* in zephyr/boards/ti/cc1352r_sensortag/cc1352r_sensortag.dts:75 */
			zephyr,code = < 0x2 >;       /* in zephyr/boards/ti/cc1352r_sensortag/cc1352r_sensortag.dts:76 */
		};
	};
};
